# myChip register map
Vendor: ARM Ltd.; Series: ARMCM3; File version: 1.2
CPU: CM3 r2p1, little endian, no MPU, no FPU, 3 interrupt priority bits
Registers are 32-bit, read-write, reset 0x0 unless marked. A register's access mark holds for its fields unless they carry their own. Offsets are from the block's base; [hi:lo] are bit positions.

## QEI0
Base 0x4002D000
Same registers: QEI1 0x4002E000, QEI2 0x4002F000
0x00 POSCNT — QEI Position Counter Register
  [31:0] POSCNT — QEI位置计数寄存器(QEI Position Counter Register)
0x04 POSINIT — QEI Position Counter Initial Register
  [31:0] POSINIT — QEI位置初始化寄存器(QEI Position Counter Initial Register)
0x08 POSMAX — QEI Position Counter Max Register
  [31:0] POSMAX — QEI位置最大值寄存器(QEI Position Counter Max Register)
0x0C POSCMP — QEI Position Counter Compare Register
  [31:0] POSCMP — QEI位置比较值寄存器 (QEI Position Counter Compare Register)
0x10 POSILAT — QEI Position Counter Index Latch Register
  [31:0] POSILAT ro — QEI位置索引锁存寄存器 (QEI Position Counter Index Latch Register)
0x14 POSLAT — QEI Position Counter Timer Latch Register
  [31:0] POSLAT ro — QEI位置定时锁存寄存器 (QEI Position Counter Timer Latch Register)
0x20 UTMR — QTIMER Counter Register
  [31:0] UTMR — QEI定时计数寄存器 (QEI Timer Counter Register）
0x24 UPRD — QTIMER Counter Period Register
  [31:0] UPRD — QEI定时周期寄存器 (QEI Timer Counter Period Register）
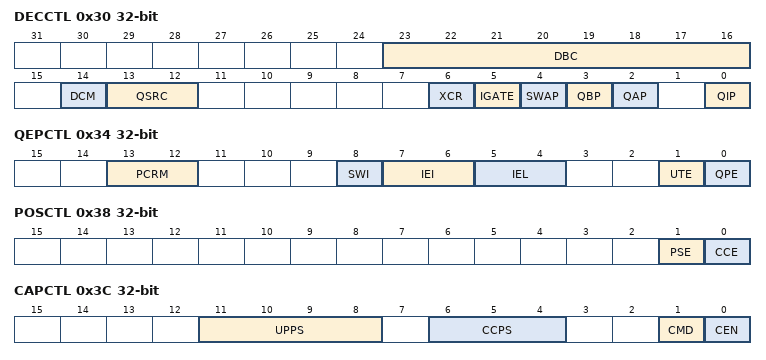
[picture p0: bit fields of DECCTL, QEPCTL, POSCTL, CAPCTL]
0x30 DECCTL — QEI Decoder Control Register
  [23:16] DBC — QEI去抖窗口设置（QEI Debounce Value）
  [14] DCM — QEI方向计数模式（QEI Direction Counter Mode）
  [13:12] QSRC — QEI位置计数器源选择（QEI Position-counter Source Selection）
  [6] XCR — QEI时钟速率控制（QEI Clock Rate Control）
  [5] IGATE — QEI索引信号使能（QEI Index Gate Enable）
  [4] SWAP — QEI正交时钟交换控制（QEI QEA/B SWAP Enable）
  [3] QBP — QEI QEB信号输入极性选择（QEI QEB Input Polarity）
  [2] QAP — QEI QEA信号输入极性选择（QEI QEA Input Polarity）
  [0] QIP — QEI Index信号输入极性选择（QEI Index Input Polarity）
0x34 QEPCTL — QEI Contorl Register
  [13:12] PCRM — QEI位置计数器复位选择（QEI Position Counter Reset Selection）
  [8] SWI — QEI位置计数器初始化使能（QEI Position Counter Software Initial Enable）
  [7:6] IEI — QEI位置计数器索引初始选择（QEI Position Counter Index Initial Selection）
  [5:4] IEL — QEI位置计数器索引锁存选择（QEI Position Counter Index Latch Selection）
  [1] UTE — QEI Timer使能（QEI Timer Enable）
  [0] QPE — QEI使能（QEI Enable）
0x38 POSCTL — QEI Position Contorl Register
  [1] PSE — QEI位置计数比较影子寄存器使能（QEI Position Counter Compare Shadow Enable）
  [0] CCE — QEI位置计数比较使能（QEI Position Counter Compare Enable）
0x3C CAPCTL — QEI Capture Control Register
  [11:8] UPPS — QEI捕获事件分频（QEI Capture Position Event Division）
  [6:4] CCPS — QEI捕获定时器分频（QEI Capture Timer Clock Division）
  [1] CMD — QEI捕获锁存模式（QEI Capture Latch Mode）
  [0] CEN — QEI捕获使能（QEI Capture Enable）
0x40 QCTMR — QEI Capture Counter Register
  [31:0] CTMR — QEI捕获计数寄存器 (QEI Capture Counter Register）
0x44 QCPRD — QEI Capture Period Register
  [31:0] CPRD ro — QEI捕获周期寄存器 (QEI Capture Period Register）
0x48 CTMRLAT — QEI Capture Counter Latch Register
  [31:0] CTMRLAT ro — QEI捕获计数锁存寄存器 (QEI Compare Counter Latch Register）
0x4C CPRDLAT — QEI Capture Period Latch Register
  [31:0] CPRDLAT ro — QEI捕获周期锁存寄存器 (QEI Capture Period Latch Register）
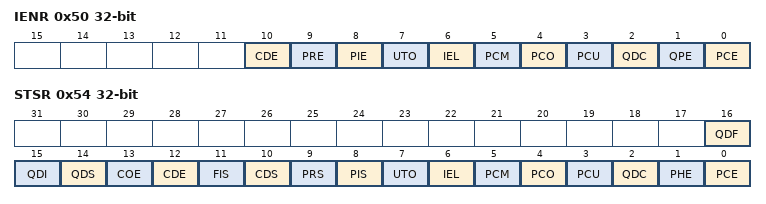
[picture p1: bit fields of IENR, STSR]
0x50 IENR — QEI Interrupt Enable Register
  [10] CDE — QEI Capture捕获成功中断使能（QEI Capture Done Interrupt Enable）
  [9] PRE — QEI位置计数器复位中断使能（QEI Position Counter Reset Interrupt Enable）
  [8] PIE — QEI位置计数器初始化中断使能（QEI Position Counter Initial Interrupt Enable）
  [7] UTO — QEI定时器溢出中断使能（QEI Timer Overflow Interrupt Enable）
  [6] IEL — QEI位置计数器锁存中断使能（QEI Position Counter Latch Interrupt Enable）
  [5] PCM — QEI位置计数器比较中断使能（QEI Position Counter Compare Interrupt Enable）
  [4] PCO — QEI位置计数器上溢中断使能（QEI Position Counter Overflow Interrupt Enable）
  [3] PCU — QEI位置计数器下溢中断使能（QEI Position Counter Underflow Interrupt Enable）
  [2] QDC — QEI正交方向变化中断使能（QEI Direction Change Interrupt Enable）
  [1] QPE — QEI相位错误中断使能（QEI Phase Error Interrupt Enable）
  [0] PCE — QEI位置计数器错误中断使能（QEI Position Counter Error Interrupt Enable）
0x54 STSR — QEI Interrupt Status Register
  [16] QDF ro — QEI首次电机转向标志位（QEI Direction First Index Status）
  [15] QDI ro — QEI每次电机转向标志位（QEI Direction Index Latch Status）
  [14] QDS ro — QEI实时电机转向标志位（QEI Direction Status）
  [13] COE — QEI捕获上溢错误标志位（QEI Capture Overflow Error Status）
  [12] CDE — QEI捕获方向错误标志位（QEI Capture Direction Error Status）
  [11] FIS ro — QEI出现首次索引标志位（QEI The First Index Status）
  [10] CDS — QEI Capture捕获成功状态标志位（QEI Capture Done Interrupt Status）
  [9] PRS — QEI位置计数器复位标志位（QEI Position Counter Reset Interrupt Status）
  [8] PIS — QEI位置计数器初始化标志位（QEI Position Counter Initial Interrupt Status）
  [7] UTO — QEI定时器溢出标志位（QEI Timer Overflow Interrupt Status）
  [6] IEL — QEI位置计数器锁存标志位（QEI Position Counter Latch Interrupt Status）
  [5] PCM — QEI位置计数器比较成功标志位（QEI Position Counter Compare Interrupt Status）
  [4] PCO — QEI位置计数器上溢标志位（QEI Position Counter Overflow Interrupt Status）
  [3] PCU — QEI位置计数器下溢标志位（QEI Position Counter Underflow Interrupt Status）
  [2] QDC — QEI正交方向变化标志位（QEI Direction Change Interrupt Status）
  [1] PHE — QEI相位错误标志位（QEI Phase Error Interrupt Status）
  [0] PCE — QEI位置计数器错误标志位（QEI Position Counter Error Interrupt Status）
